# STM32F103 register map
File version: 1.0
STM32F103xx
Registers are 32-bit, read-write, reset 0x0 unless marked. A register's access mark holds for its fields unless they carry their own. Offsets are from the block's base; lines under a group give offsets from that group; [hi:lo] are bit positions; {n}, {i} and the like mark numbered series; 'fields as' and 'values as' point back to an identical list; <NAME> marks a mode.

## Memory map
0x40013800 USART1 — Universal synchronous asynchronous receiver transmitter

## Interrupts
37 USART1

## USART1 — Universal synchronous asynchronous receiver transmitter
Base 0x40013800
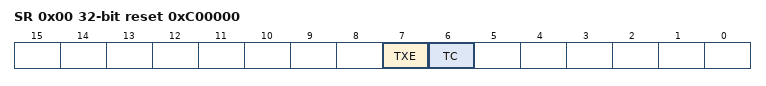
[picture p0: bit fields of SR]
0x00 SR ro reset 0xC00000 — Status register
  [7] TXE — Transmit data register empty
  [6] TC rw — Transmission complete
0x04 DR — Data register
  [8:0] DR — Data value
0x08 CR write-1-clears — Control register with side effects
  [0] EIE
